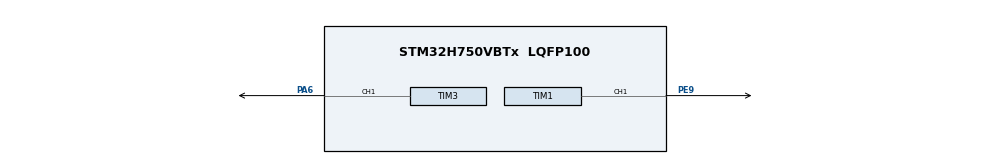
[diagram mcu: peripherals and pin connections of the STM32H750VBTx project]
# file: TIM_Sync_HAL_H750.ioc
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Mcu.Family=STM32H7
Mcu.Name=STM32H750VBTx
Mcu.Package=LQFP100
NVIC.PriorityGroup=NVIC_PRIORITYGROUP_4
PA13\ (JTMS/SWDIO).Mode=Serial_Wire
PA13\ (JTMS/SWDIO).Signal=DEBUG_JTMS-SWDIO
PA14\ (JTCK/SWCLK).Mode=Serial_Wire
PA14\ (JTCK/SWCLK).Signal=DEBUG_JTCK-SWCLK
PA6.Signal=S_TIM3_CH1
PE9.Signal=S_TIM1_CH1
PH0-OSC_IN\ (PH0).Mode=HSE-External-Oscillator
PH0-OSC_IN\ (PH0).Signal=RCC_OSC_IN
PH1-OSC_OUT\ (PH1).Mode=HSE-External-Oscillator
PH1-OSC_OUT\ (PH1).Signal=RCC_OSC_OUT
ProjectManager.HeapSize=0x200
ProjectManager.StackSize=0x400
ProjectManager.TargetToolchain=STM32CubeIDE
RCC.ADCFreq_Value=50390625
RCC.APB1Freq_Value=120000000
RCC.APB2Freq_Value=120000000
RCC.APB3Freq_Value=120000000
RCC.APB4Freq_Value=120000000
RCC.CortexFreq_Value=240000000
RCC.DIVM1=25
RCC.DIVN1=480
RCC.HCLKFreq_Value=120000000
RCC.HPRE=RCC_HCLK_DIV2
RCC.PLLSourceVirtual=RCC_PLLSOURCE_HSE
RCC.SYSCLKFreq_VALUE=240000000
RCC.SYSCLKSource=RCC_SYSCLKSOURCE_PLLCLK
RCC.USBFreq_Value=240000000
SH.S_TIM1_CH1.0=TIM1_CH1,PWM Generation1 CH1
SH.S_TIM3_CH1.0=TIM3_CH1,PWM Generation1 CH1
TIM1.AutoReloadPreload=TIM_AUTORELOAD_PRELOAD_ENABLE
TIM1.Channel-PWM\ Generation1\ CH1=TIM_CHANNEL_1
TIM1.Period=999
TIM1.Prescaler=119
TIM1.Pulse-PWM\ Generation1\ CH1=500
TIM1.TIM_MasterOutputTrigger=TIM_TRGO_ENABLE
TIM3.AutoReloadPreload=TIM_AUTORELOAD_PRELOAD_ENABLE
TIM3.Channel-PWM\ Generation1\ CH1=TIM_CHANNEL_1
TIM3.Period=999
TIM3.Prescaler=119
TIM3.Pulse-PWM\ Generation1\ CH1=500
TIM3.TIM_MasterOutputTrigger=TIM_TRGO_RESET
VP_TIM1_VS_ClockSourceINT.Mode=Internal
VP_TIM3_VS_ClockSourceINT.Mode=Internal
VP_TIM3_VS_ClockSourceITR.Mode=TriggerSource_ITR0
VP_TIM3_VS_ControllerModeTrigger.Mode=Trigger Mode
board=custom

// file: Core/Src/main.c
/* USER CODE BEGIN Header */
/**
  ******************************************************************************
  * @file           : main.c
  * @brief          : Main program body
  ******************************************************************************
  * @attention
  *
  * Copyright (c) 2023 STMicroelectronics.
  * All rights reserved.
  *
  * This software is licensed under terms that can be found in the LICENSE file
  * in the root directory of this software component.
  * If no LICENSE file comes with this software, it is provided AS-IS.
  *
  ******************************************************************************
  */
/* USER CODE END Header */
#include "main.h"

TIM_HandleTypeDef htim1;
TIM_HandleTypeDef htim3;

void SystemClock_Config(void);
static void MX_GPIO_Init(void);
static void MX_TIM1_Init(void);
static void MX_TIM3_Init(void);

int main(void)
{

  /* MCU Configuration--------------------------------------------------------*/

  /* Reset of all peripherals, Initializes the Flash interface and the Systick. */
  HAL_Init();

  /* Configure the system clock */
  SystemClock_Config();

  /* Initialize all configured peripherals */
  MX_GPIO_Init();
  MX_TIM1_Init();
  MX_TIM3_Init();

  /* Infinite loop */
  /* USER CODE BEGIN WHILE */

  HAL_TIM_PWM_Start(&htim3, TIM_CHANNEL_1); // 使能TIM3
//  HAL_Delay(233); // 这里不管设置多少延时，TIM3一定都是TIM1使能后才会开始工作
                    // 不过因为当前PWM输出参数设置下，上面函数执行后 TIM3_CH1 通道就会置于高电平状态
  HAL_TIM_PWM_Start(&htim1, TIM_CHANNEL_1); // 使能TIM1

  while (1)
  {
    /* USER CODE END WHILE */

  }
}

void SystemClock_Config(void)
{
  RCC_OscInitTypeDef RCC_OscInitStruct = {0};
  RCC_ClkInitTypeDef RCC_ClkInitStruct = {0};

  /** Supply configuration update enable
  */
  HAL_PWREx_ConfigSupply(PWR_LDO_SUPPLY);

  /** Configure the main internal regulator output voltage
  */
  __HAL_PWR_VOLTAGESCALING_CONFIG(PWR_REGULATOR_VOLTAGE_SCALE2);

  while(!__HAL_PWR_GET_FLAG(PWR_FLAG_VOSRDY)) {}

  /** Initializes the RCC Oscillators according to the specified parameters
  * in the RCC_OscInitTypeDef structure.
  */
  RCC_OscInitStruct.OscillatorType = RCC_OSCILLATORTYPE_HSE;
  RCC_OscInitStruct.HSEState = RCC_HSE_ON;
  RCC_OscInitStruct.PLL.PLLState = RCC_PLL_ON;
  RCC_OscInitStruct.PLL.PLLSource = RCC_PLLSOURCE_HSE;
  RCC_OscInitStruct.PLL.PLLM = 25;
  RCC_OscInitStruct.PLL.PLLN = 480;
  RCC_OscInitStruct.PLL.PLLP = 2;
  RCC_OscInitStruct.PLL.PLLQ = 2;
  RCC_OscInitStruct.PLL.PLLR = 2;
  RCC_OscInitStruct.PLL.PLLRGE = RCC_PLL1VCIRANGE_0;
  RCC_OscInitStruct.PLL.PLLVCOSEL = RCC_PLL1VCOWIDE;
  RCC_OscInitStruct.PLL.PLLFRACN = 0;
  if (HAL_RCC_OscConfig(&RCC_OscInitStruct) != HAL_OK)
  {
    Error_Handler();
  }

  /** Initializes the CPU, AHB and APB buses clocks
  */
  RCC_ClkInitStruct.ClockType = RCC_CLOCKTYPE_HCLK|RCC_CLOCKTYPE_SYSCLK
                              |RCC_CLOCKTYPE_PCLK1|RCC_CLOCKTYPE_PCLK2
                              |RCC_CLOCKTYPE_D3PCLK1|RCC_CLOCKTYPE_D1PCLK1;
  RCC_ClkInitStruct.SYSCLKSource = RCC_SYSCLKSOURCE_PLLCLK;
  RCC_ClkInitStruct.SYSCLKDivider = RCC_SYSCLK_DIV1;
  RCC_ClkInitStruct.AHBCLKDivider = RCC_HCLK_DIV2;
  RCC_ClkInitStruct.APB3CLKDivider = RCC_APB3_DIV1;
  RCC_ClkInitStruct.APB1CLKDivider = RCC_APB1_DIV1;
  RCC_ClkInitStruct.APB2CLKDivider = RCC_APB2_DIV1;
  RCC_ClkInitStruct.APB4CLKDivider = RCC_APB4_DIV1;

  if (HAL_RCC_ClockConfig(&RCC_ClkInitStruct, FLASH_LATENCY_2) != HAL_OK)
  {
    Error_Handler();
  }
}

static void MX_TIM1_Init(void)
{

  TIM_ClockConfigTypeDef sClockSourceConfig = {0};
  TIM_MasterConfigTypeDef sMasterConfig = {0};
  TIM_OC_InitTypeDef sConfigOC = {0};
  TIM_BreakDeadTimeConfigTypeDef sBreakDeadTimeConfig = {0};

  htim1.Instance = TIM1;
  htim1.Init.Prescaler = 119;
  htim1.Init.CounterMode = TIM_COUNTERMODE_UP;
  htim1.Init.Period = 999;
  htim1.Init.ClockDivision = TIM_CLOCKDIVISION_DIV1;
  htim1.Init.RepetitionCounter = 0;
  htim1.Init.AutoReloadPreload = TIM_AUTORELOAD_PRELOAD_ENABLE;
  if (HAL_TIM_Base_Init(&htim1) != HAL_OK)
  {
    Error_Handler();
  }
  sClockSourceConfig.ClockSource = TIM_CLOCKSOURCE_INTERNAL;
  if (HAL_TIM_ConfigClockSource(&htim1, &sClockSourceConfig) != HAL_OK)
  {
    Error_Handler();
  }
  if (HAL_TIM_PWM_Init(&htim1) != HAL_OK)
  {
    Error_Handler();
  }
  sMasterConfig.MasterOutputTrigger = TIM_TRGO_ENABLE;
  sMasterConfig.MasterOutputTrigger2 = TIM_TRGO2_RESET;
  sMasterConfig.MasterSlaveMode = TIM_MASTERSLAVEMODE_DISABLE;
  if (HAL_TIMEx_MasterConfigSynchronization(&htim1, &sMasterConfig) != HAL_OK)
  {
    Error_Handler();
  }
  sConfigOC.OCMode = TIM_OCMODE_PWM1;
  sConfigOC.Pulse = 500;
  sConfigOC.OCPolarity = TIM_OCPOLARITY_HIGH;
  sConfigOC.OCNPolarity = TIM_OCNPOLARITY_HIGH;
  sConfigOC.OCFastMode = TIM_OCFAST_DISABLE;
  sConfigOC.OCIdleState = TIM_OCIDLESTATE_RESET;
  sConfigOC.OCNIdleState = TIM_OCNIDLESTATE_RESET;
  if (HAL_TIM_PWM_ConfigChannel(&htim1, &sConfigOC, TIM_CHANNEL_1) != HAL_OK)
  {
    Error_Handler();
  }
  sBreakDeadTimeConfig.OffStateRunMode = TIM_OSSR_DISABLE;
  sBreakDeadTimeConfig.OffStateIDLEMode = TIM_OSSI_DISABLE;
  sBreakDeadTimeConfig.LockLevel = TIM_LOCKLEVEL_OFF;
  sBreakDeadTimeConfig.DeadTime = 0;
  sBreakDeadTimeConfig.BreakState = TIM_BREAK_DISABLE;
  sBreakDeadTimeConfig.BreakPolarity = TIM_BREAKPOLARITY_HIGH;
  sBreakDeadTimeConfig.BreakFilter = 0;
  sBreakDeadTimeConfig.Break2State = TIM_BREAK2_DISABLE;
  sBreakDeadTimeConfig.Break2Polarity = TIM_BREAK2POLARITY_HIGH;
  sBreakDeadTimeConfig.Break2Filter = 0;
  sBreakDeadTimeConfig.AutomaticOutput = TIM_AUTOMATICOUTPUT_DISABLE;
  if (HAL_TIMEx_ConfigBreakDeadTime(&htim1, &sBreakDeadTimeConfig) != HAL_OK)
  {
    Error_Handler();
  }
  HAL_TIM_MspPostInit(&htim1);

}

static void MX_TIM3_Init(void)
{

  TIM_ClockConfigTypeDef sClockSourceConfig = {0};
  TIM_SlaveConfigTypeDef sSlaveConfig = {0};
  TIM_MasterConfigTypeDef sMasterConfig = {0};
  TIM_OC_InitTypeDef sConfigOC = {0};

  htim3.Instance = TIM3;
  htim3.Init.Prescaler = 119;
  htim3.Init.CounterMode = TIM_COUNTERMODE_UP;
  htim3.Init.Period = 999;
  htim3.Init.ClockDivision = TIM_CLOCKDIVISION_DIV1;
  htim3.Init.AutoReloadPreload = TIM_AUTORELOAD_PRELOAD_ENABLE;
  if (HAL_TIM_Base_Init(&htim3) != HAL_OK)
  {
    Error_Handler();
  }
  sClockSourceConfig.ClockSource = TIM_CLOCKSOURCE_INTERNAL;
  if (HAL_TIM_ConfigClockSource(&htim3, &sClockSourceConfig) != HAL_OK)
  {
    Error_Handler();
  }
  if (HAL_TIM_PWM_Init(&htim3) != HAL_OK)
  {
    Error_Handler();
  }
  sSlaveConfig.SlaveMode = TIM_SLAVEMODE_TRIGGER;
  sSlaveConfig.InputTrigger = TIM_TS_ITR0;
  if (HAL_TIM_SlaveConfigSynchro(&htim3, &sSlaveConfig) != HAL_OK)
  {
    Error_Handler();
  }
  sMasterConfig.MasterOutputTrigger = TIM_TRGO_RESET;
  sMasterConfig.MasterSlaveMode = TIM_MASTERSLAVEMODE_DISABLE;
  if (HAL_TIMEx_MasterConfigSynchronization(&htim3, &sMasterConfig) != HAL_OK)
  {
    Error_Handler();
  }
  sConfigOC.OCMode = TIM_OCMODE_PWM1;
  sConfigOC.Pulse = 500;
  sConfigOC.OCPolarity = TIM_OCPOLARITY_HIGH;
  sConfigOC.OCFastMode = TIM_OCFAST_DISABLE;
  if (HAL_TIM_PWM_ConfigChannel(&htim3, &sConfigOC, TIM_CHANNEL_1) != HAL_OK)
  {
    Error_Handler();
  }
  HAL_TIM_MspPostInit(&htim3);

}

static void MX_GPIO_Init(void)
{

  /* GPIO Ports Clock Enable */
  __HAL_RCC_GPIOH_CLK_ENABLE();
  __HAL_RCC_GPIOA_CLK_ENABLE();
  __HAL_RCC_GPIOE_CLK_ENABLE();

}

void Error_Handler(void)
{
  __disable_irq();
  while (1)
  {
  }
}
